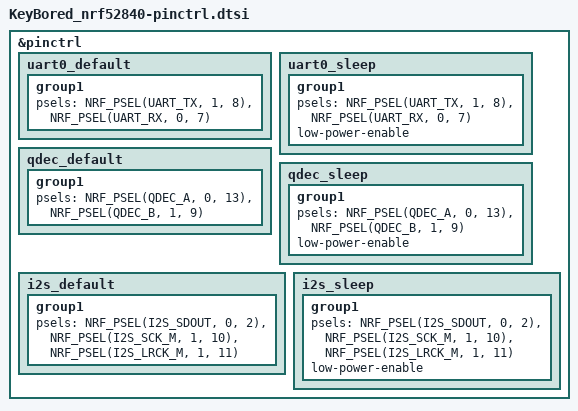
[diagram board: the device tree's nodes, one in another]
&pinctrl {
	uart0_default: uart0_default {
		group1 {
			psels = <NRF_PSEL(UART_TX, 1,  8)>,
				<NRF_PSEL(UART_RX, 0,  7)>;
		};
	};

	uart0_sleep: uart0_sleep {
		group1 {
			psels = <NRF_PSEL(UART_TX, 1,  8)>,
				<NRF_PSEL(UART_RX, 0,  7)>;
			low-power-enable;
		};
	};

	qdec_default: qdec_default {
		group1 {
			psels = <NRF_PSEL(QDEC_A, 0, 13)>,
				<NRF_PSEL(QDEC_B, 1,  9)>;
		};
	};

	qdec_sleep: qdec_sleep {
		group1 {
			psels = <NRF_PSEL(QDEC_A, 0, 13)>,
				<NRF_PSEL(QDEC_B, 1,  9)>;
			low-power-enable;
		};
	};

	i2s_default: i2s_default {
		group1 {
			psels = <NRF_PSEL(I2S_SDOUT, 0,  2)>,
				<NRF_PSEL(I2S_SCK_M, 1, 10)>,
				<NRF_PSEL(I2S_LRCK_M, 1, 11)>;
		};
	};

	i2s_sleep: i2s_sleep {
		group1 {
			psels = <NRF_PSEL(I2S_SDOUT, 0,  2)>,
				<NRF_PSEL(I2S_SCK_M, 1, 10)>,
				<NRF_PSEL(I2S_LRCK_M, 1, 11)>;
			low-power-enable;
		};
	};
};
